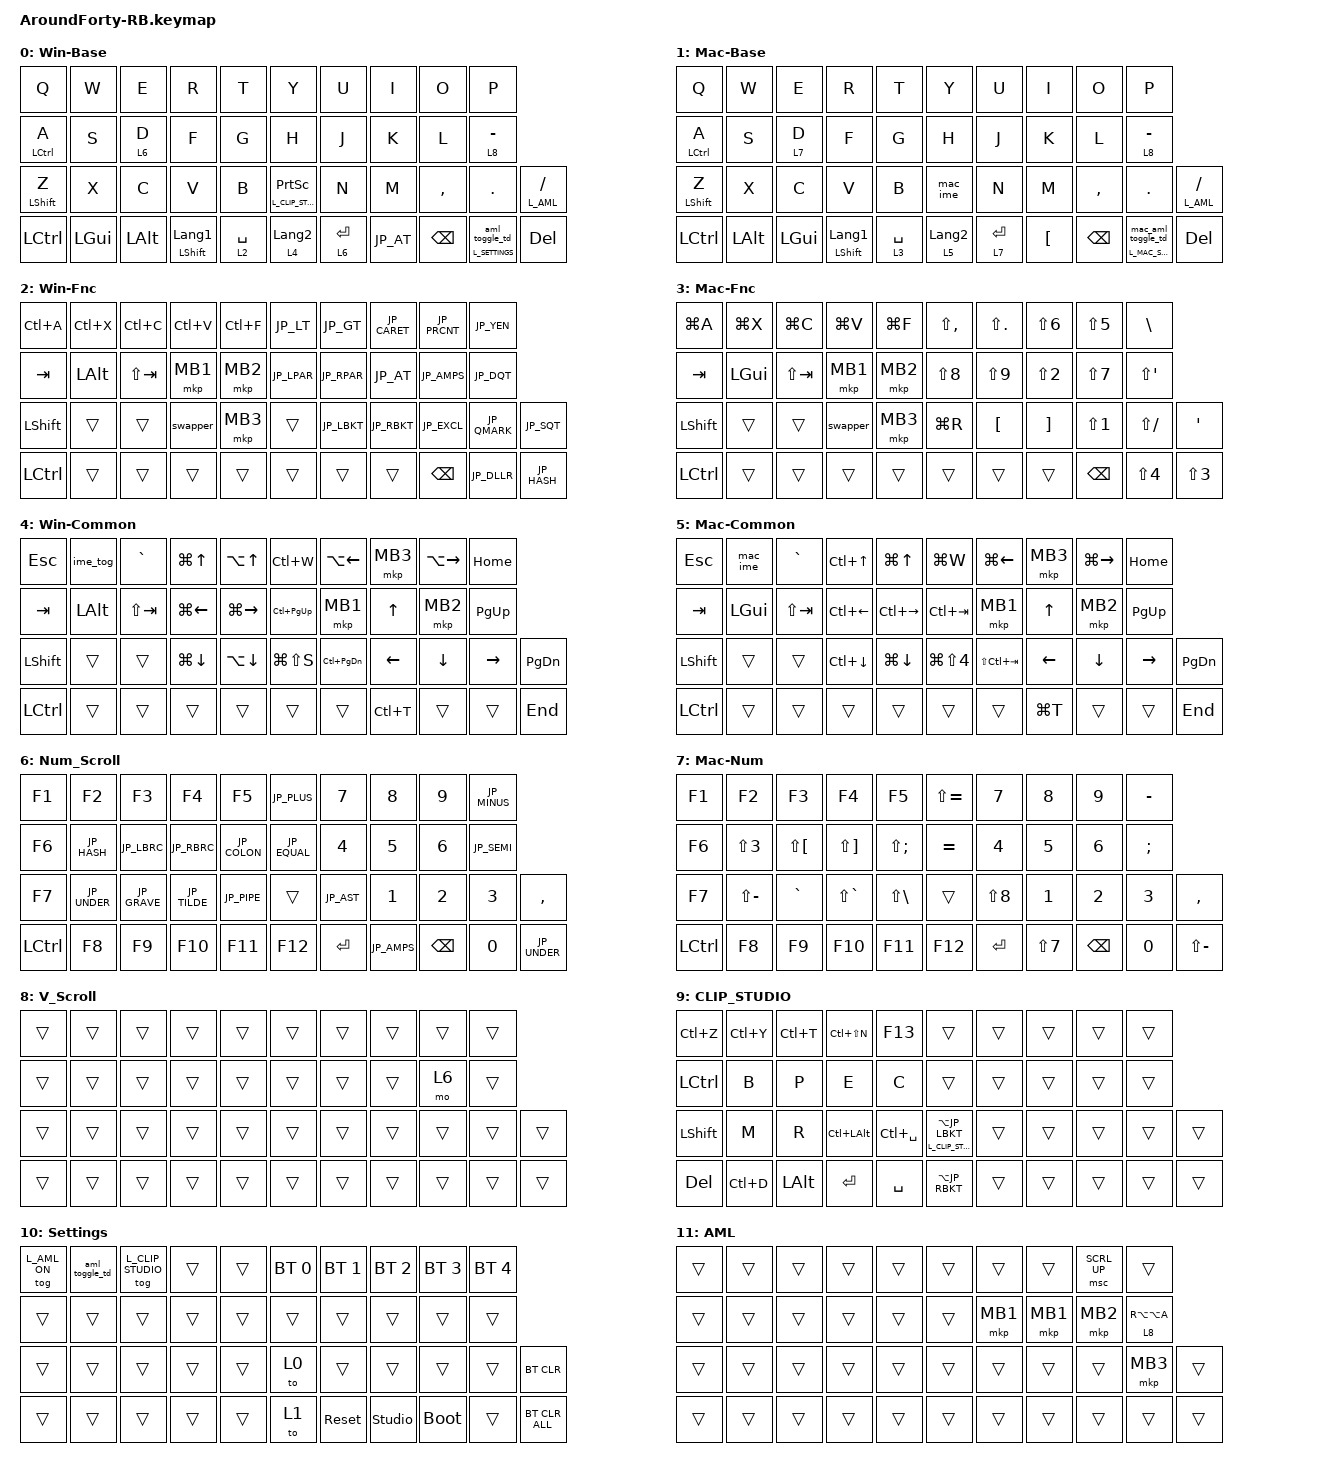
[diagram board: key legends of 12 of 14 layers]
#include<behaviors/rgbled_widget.dtsi>
#include <behaviors.dtsi>
#include <dt-bindings/zmk/bt.h>
#include <dt-bindings/zmk/keys.h>
#include <dt-bindings/zmk/pointing.h>

// JIS配列用の記号変換マクロ
#define JP_LT LS(COMMA)           // <
#define JP_GT LS(DOT)             // >
#define JP_CARET EQUAL            // ^
#define JP_PRCNT LS(N5)           // %
#define JP_DLLR LS(N4)            // $
#define JP_LPAR LS(N8)            // (
#define JP_RPAR LS(N9)            // )
#define JP_AT LEFT_BRACKET        // @
#define JP_AMPS LS(N6)            // &
#define JP_DQT LS(N2)             // "
#define JP_COLON SINGLE_QUOTE     // :
#define JP_LBKT RIGHT_BRACKET     // [
#define JP_RBKT NON_US_HASH       // ]
#define JP_EXCL LS(N1)            // !
#define JP_QMARK LS(SLASH)        // ?
#define JP_SQT LS(N7)             // '
#define JP_YEN INTERNATIONAL_3    // Yen (Backslash)
#define JP_HASH LS(N3)            // #
#define JP_MINUS MINUS            // -
#define JP_PLUS LS(SEMICOLON)     // +
#define JP_AST LS(SINGLE_QUOTE)   // *
#define JP_EQUAL LS(MINUS)        // =
#define JP_SEMI SEMICOLON            // ;
#define JP_UNDER LS(INTERNATIONAL_1) // _
#define JP_TILDE LS(EQUAL)           // ~
#define JP_PIPE LS(INTERNATIONAL_3)  // |
#define JP_GRAVE LS(LEFT_BRACKET)    // `
#define JP_LBRC LS(RIGHT_BRACKET)    // {
#define JP_RBRC LS(NON_US_HASH)      // }

// Higher layer numbers take precedence. CLIP_STUDIO stays below both Settings layers.
#define L_CLIP_STUDIO 9
#define L_SETTINGS 10
#define L_AML 11
#define L_AML_ON 12
#define L_MAC_SETTINGS 13

&mt {
    flavor = "balanced";
    quick-tap-ms = <0>;
};

/ {
    behaviors {
        // Internal split command; the central sends the actual layer state.
        af_led: af_led {
            compatible = "zmk,behavior-aroundforty-status-led";
            #binding-cells = <1>;
            clip-layer = <L_CLIP_STUDIO>;
            aml-layer = <L_AML>;
            aml-on-layer = <L_AML_ON>;
        };
    };

    combos {
        compatible = "zmk,combos";

        Escape {
            bindings = <&kp ESCAPE>;
            key-positions = <0 1>;
        };
    };

    macros {
        to_layer_0: to_layer_0 {
            compatible = "zmk,behavior-macro-one-param";
            #binding-cells = <1>;
            bindings = <&to 0 &macro_param_1to1 &kp MACRO_PLACEHOLDER>;
            label = "TO_LAYER_0";
        };

        // Windows用入力切り替え：Win + Space
        ime_tog: ime_toggle {
            compatible = "zmk,behavior-macro";
            #binding-cells = <0>;
            bindings =
                <&macro_press>,
                <&kp LGUI>,
                <&macro_tap>,
                <&kp SPACE>,
                <&macro_release>,
                <&kp LGUI>;
        };

        // macOS用入力切り替え：Ctrl + Space
        mac_ime: mac_ime_toggle {
            compatible = "zmk,behavior-macro";
            #binding-cells = <0>;
            bindings =
                <&macro_press>,
                <&kp LCTRL>,
                <&macro_tap>,
                <&kp SPACE>,
                <&macro_release>,
                <&kp LCTRL>;
        };

        // AMLだけ確定OFFにする。クリスタとOSベースは維持する。
        aml_off: aml_off {
            compatible = "zmk,behavior-macro";
            #binding-cells = <0>;
            label = "AML_OFF";
            wait-ms = <0>;
            bindings
                = <&macro_release>, <&mo L_AML_ON>, <&mo L_AML>;
        };

        aml_toggle_td: aml_toggle_td {
            compatible = "zmk,behavior-tap-dance";
            #binding-cells = <0>;
            label = "AML_TOGGLE_TD";
            tapping-term-ms = <300>;
            bindings = <&aml_off>, <&tog L_AML_ON>;
        };

        // Mac側もAMLだけ解除し、クリスタとUS配列を維持する。
        mac_aml_off: mac_aml_off {
            compatible = "zmk,behavior-macro";
            #binding-cells = <0>;
            label = "MAC_AML_OFF";
            wait-ms = <0>;
            bindings
                = <&macro_release>, <&mo L_AML_ON>, <&mo L_AML>;
        };

        mac_aml_toggle_td: mac_aml_toggle_td {
            compatible = "zmk,behavior-tap-dance";
            #binding-cells = <0>;
            label = "MAC_AML_TOGGLE_TD";
            tapping-term-ms = <300>;
            bindings = <&mac_aml_off>, <&tog L_AML_ON>;
        };
    };

    behaviors {
        lt_to_layer_0: lt_to_layer_0 {
            compatible = "zmk,behavior-hold-tap";
            label = "LAYER_TAP_TO_0";
            bindings = <&mo>, <&to_layer_0>;
            #binding-cells = <2>;
            tapping-term-ms = <200>;
        };

        lt_num: lt_num {
            compatible = "zmk,behavior-hold-tap";
            label = "LT_NUM";
            bindings = <&mo>, <&kp>;
            #binding-cells = <2>;
            tapping-term-ms = <150>;
            quick-tap-ms = <150>;        // これを入れると Enter の連打が可能になります
        };

        mt_z_shift: mt_z_shift {
            compatible = "zmk,behavior-hold-tap";
            label = "MT_Z_SHIFT";
            bindings = <&kp>, <&kp>;
            #binding-cells = <2>;
            flavor = "balanced";
            quick-tap-ms = <0>;
            tapping-term-ms = <250>;
        };

        mt_a_ctrl: mt_a_ctrl {
            compatible = "zmk,behavior-hold-tap";
            label = "MT_A_CTRL";
            bindings = <&kp>, <&kp>;
            #binding-cells = <2>;
            flavor = "balanced";
            quick-tap-ms = <0>;
            tapping-term-ms = <250>;
        };

        lt_typ: layer_tap_typing {
            compatible = "zmk,behavior-hold-tap";
            label = "LAYER_TAP_TYPING";
            #binding-cells = <2>;
            tapping-term-ms = <200>;
            flavor = "tap-preferred";
            require-prior-idle-ms = <150>;
            bindings = <&mo>, <&kp>;
        };

        lt_clip_toggle: clip_toggle_hold_tap {
            compatible = "zmk,behavior-hold-tap";
            label = "CLIP_TOGGLE_HOLD_TAP";
            #binding-cells = <2>;
            tapping-term-ms = <200>;
            flavor = "tap-preferred";
            quick-tap-ms = <0>;
            bindings = <&tog>, <&kp>;
        };

        settings_hold_tap: settings_hold_tap {
            compatible = "zmk,behavior-hold-tap";
            label = "SETTINGS_HOLD_TAP";
            #binding-cells = <2>;
            tapping-term-ms = <200>;
            flavor = "balanced";
            quick-tap-ms = <0>;
            bindings = <&mo>, <&aml_toggle_td>;
        };

        mac_settings_hold_tap: mac_settings_hold_tap {
            compatible = "zmk,behavior-hold-tap";
            label = "MAC_SETTINGS_HOLD_TAP";
            #binding-cells = <2>;
            tapping-term-ms = <200>;
            flavor = "balanced";
            quick-tap-ms = <0>;
            bindings = <&mo>, <&mac_aml_toggle_td>;
        };

        scroll_up_down: behavior_sensor_rotate_mouse_wheel_up_down {
            compatible = "zmk,behavior-sensor-rotate";
            #sensor-binding-cells = <0>;
            bindings = <&msc SCRL_UP>, <&msc SCRL_DOWN>;
            tap-ms = <20>;
        };

        swapper: swapper {
            compatible = "zmk,behavior-tri-state";
            #binding-cells = <0>;
            bindings = <&kt LALT>, <&kp TAB>, <&kt LALT>;
        };
    };

    keymap {
        compatible = "zmk,keymap";

        Win-Base { // layer 0
            display-name = "Win-Base";
            bindings = <
                &kp Q                    &kp W          &kp E          &kp R                  &kp T                  &kp Y                   &kp U            &kp I             &kp O             &kp P
                &mt_a_ctrl LCTRL A       &kp S          &lt_typ 6 D      &kp F                  &kp G                  &kp H                   &kp J            &kp K             &kp L             &lt 8 MINUS
                &mt_z_shift LEFT_SHIFT Z &kp X          &kp C          &kp V                  &kp B                  &lt_clip_toggle L_CLIP_STUDIO PRINTSCREEN &kp N            &kp M             &kp COMMA         &kp DOT   &lt L_AML SLASH
                &kp LCTRL                &kp LGUI       &kp LALT       &mt LSHFT LANGUAGE_1   &lt 2 SPACE            &lt 4 LANGUAGE_2        &lt_num 6 ENTER  &kp JP_AT         &kp BSPC          &settings_hold_tap L_SETTINGS 0 &kp DEL
            >;
        };

        Mac-Base { // layer 1
            display-name = "Mac-Base";
            bindings = <
                &kp Q                    &kp W          &kp E          &kp R                  &kp T                  &kp Y                   &kp U            &kp I             &kp O             &kp P
                &mt_a_ctrl LCTRL A       &kp S          &lt_typ 7 D      &kp F                  &kp G                  &kp H                   &kp J            &kp K             &kp L             &lt 8 MINUS
                &mt_z_shift LEFT_SHIFT Z &kp X          &kp C          &kp V                  &kp B                  &mac_ime                &kp N            &kp M             &kp COMMA         &kp DOT   &lt L_AML SLASH
                &kp LCTRL                &kp LEFT_ALT   &kp LEFT_GUI   &mt LSHFT LANGUAGE_1   &lt 3 SPACE            &lt 5 LANGUAGE_2        &lt_num 7 ENTER  &kp LEFT_BRACKET  &kp BSPC          &mac_settings_hold_tap L_MAC_SETTINGS 0 &kp DEL
            >;
        };

        Win-Fnc { // layer 2
            display-name = "Win-Fnc";
            bindings = <
                &kp LC(A)                &kp LC(X)      &kp LC(C)      &kp LC(V)              &kp LC(F)              &kp JP_LT               &kp JP_GT        &kp JP_CARET      &kp JP_PRCNT      &kp JP_YEN
                &kp TAB                  &kp LEFT_ALT   &kp LS(TAB)    &mkp MB1               &mkp MB2               &kp JP_LPAR             &kp JP_RPAR      &kp JP_AT         &kp JP_AMPS       &kp JP_DQT
                &kp LEFT_SHIFT           &trans         &trans         &swapper               &mkp MB3               &trans                  &kp JP_LBKT      &kp JP_RBKT       &kp JP_EXCL       &kp JP_QMARK &kp JP_SQT
                &kp LCTRL                &trans         &trans         &trans                 &trans                 &trans                  &trans           &trans            &kp BACKSPACE     &kp JP_DLLR &kp JP_HASH
            >;
        };

        Mac-Fnc { // layer 3
            display-name = "Mac-Fnc";
            bindings = <
                &kp LG(A)                &kp LG(X)      &kp LG(C)      &kp LG(V)              &kp LG(F)              &kp LS(COMMA)           &kp LS(DOT)      &kp LS(N6)        &kp LS(N5)        &kp BACKSLASH
                &kp TAB                  &kp LEFT_GUI   &kp LS(TAB)    &mkp MB1               &mkp MB2               &kp LS(N8)              &kp LS(N9)       &kp LS(N2)        &kp LS(N7)        &kp LS(SINGLE_QUOTE)
                &kp LEFT_SHIFT           &trans         &trans         &swapper               &mkp MB3               &kp LG(R)               &kp LEFT_BRACKET &kp RIGHT_BRACKET &kp LS(N1)        &kp LS(SLASH) &kp SINGLE_QUOTE
                &kp LCTRL                &trans         &trans         &trans                 &trans                 &trans                  &trans           &trans            &kp BACKSPACE     &kp LS(N4)   &kp LS(N3)
            >;
        };

        Win-Common { // layer 4
            display-name = "Win-Common";
            bindings = <
                &kp ESC                  &ime_tog       &kp GRAVE      &kp LG(UP_ARROW)       &kp LA(UP_ARROW)       &kp LC(W)               &kp LA(LEFT_ARROW) &mkp MB3         &kp LA(RIGHT_ARROW) &kp HOME
                &kp TAB                  &kp LEFT_ALT   &kp LS(TAB)    &kp LG(LEFT_ARROW)     &kp LG(RIGHT_ARROW)    &kp LC(PAGE_UP)         &mkp MB1           &kp UP_ARROW     &mkp MB2            &kp PAGE_UP
                &kp LSHFT                &trans         &trans         &kp LG(DOWN_ARROW)     &kp LA(DOWN_ARROW)     &kp LG(LS(S))           &kp LC(PAGE_DOWN)  &kp LEFT_ARROW   &kp DOWN_ARROW      &kp RIGHT_ARROW &kp PAGE_DOWN
                &kp LCTRL                &trans         &trans         &trans                 &trans                 &trans                  &trans             &kp LC(T)        &trans              &trans        &kp END
            >;
        };

        Mac-Common { // layer 5
            display-name = "Mac-Common";
            bindings = <
                &kp ESC                  &mac_ime       &kp GRAVE      &kp LC(UP_ARROW)       &kp LG(UP_ARROW)       &kp LG(W)               &kp LG(LEFT_ARROW) &mkp MB3         &kp LG(RIGHT_ARROW) &kp HOME
                &kp TAB                  &kp LEFT_GUI   &kp LS(TAB)    &kp LC(LEFT_ARROW)     &kp LC(RIGHT_ARROW)    &kp LC(TAB)             &mkp MB1           &kp UP_ARROW     &mkp MB2            &kp PAGE_UP
                &kp LSHFT                &trans         &trans         &kp LC(DOWN_ARROW)     &kp LG(DOWN_ARROW)     &kp LG(LS(N4))          &kp LS(LC(TAB))    &kp LEFT_ARROW   &kp DOWN_ARROW      &kp RIGHT_ARROW &kp PAGE_DOWN
                &kp LCTRL                &trans         &trans         &trans                 &trans                 &trans                  &trans             &kp LG(T)        &trans              &trans        &kp END
            >;
        };

        Num_Scroll { // layer 6
            bindings = <
                    &kp F1                   &kp F2         &kp F3         &kp F4                 &kp F5                 &kp JP_PLUS             &kp N7            &kp N8            &kp N9            &kp JP_MINUS
                    &kp F6                   &kp JP_HASH         &kp JP_LBRC    &kp JP_RBRC            &kp JP_COLON           &kp JP_EQUAL            &kp N4            &kp N5            &kp N6            &kp JP_SEMI
                    &kp F7                   &kp JP_UNDER         &kp JP_GRAVE   &kp JP_TILDE           &kp JP_PIPE            &trans                  &kp JP_AST        &kp N1            &kp N2            &kp N3          &kp COMMA
                    &kp LCTRL                &kp F8         &kp F9         &kp F10                &kp F11                &kp F12                 &kp ENTER         &kp JP_AMPS       &kp BSPC          &kp N0        &kp JP_UNDER
            >;
        };

        Mac_Num_Scroll { // layer 7
            display-name = "Mac-Num";
            bindings = <
                    &kp F1                   &kp F2         &kp F3         &kp F4                 &kp F5                 &kp LS(EQUAL)           &kp N7            &kp N8            &kp N9            &kp MINUS
                    &kp F6                   &kp LS(N3)     &kp LS(LEFT_BRACKET) &kp LS(RIGHT_BRACKET) &kp LS(SEMICOLON)  &kp EQUAL               &kp N4            &kp N5            &kp N6            &kp SEMICOLON
                    &kp F7                   &kp LS(MINUS)  &kp GRAVE      &kp LS(GRAVE)          &kp LS(BACKSLASH)      &trans                  &kp LS(N8)            &kp N1         &kp N2            &kp N3          &kp COMMA
                    &kp LCTRL                &kp F8         &kp F9         &kp F10                &kp F11                &kp F12             &kp ENTER         &kp LS(N7)        &kp BSPC          &kp N0          &kp LS(MINUS)
            >;
        };

        V_Scroll { // layer 8
            bindings = <
                &trans                   &trans         &trans         &trans                 &trans                 &trans                  &trans            &trans            &trans            &trans
                &trans                   &trans         &trans         &trans                 &trans                 &trans                  &trans            &trans            &mo 6             &trans
                &trans                   &trans         &trans         &trans                 &trans                 &trans                  &trans            &trans            &trans            &trans        &trans
                &trans                   &trans         &trans         &trans                 &trans                 &trans                  &trans            &trans            &trans            &trans        &trans
            >;
        };

        CLIP_STUDIO { // layer 9: Windows/JIS CLIP STUDIO PAINT shortcuts
            display-name = "CLIP_STUDIO";
            bindings = <
                &kp LC(Z)         &kp LC(Y)         &kp LC(T)         &kp LC(LS(N))     &kp F13           &trans             &trans       &trans       &trans       &trans
                &kp LCTRL         &kp B             &kp P             &kp E             &kp C             &trans             &trans       &trans       &trans       &trans
                &kp LSHFT         &kp M             &kp R             &kp LC(LALT)      &kp LC(SPACE)     &lt_clip_toggle L_CLIP_STUDIO LA(JP_LBKT) &trans &trans &trans &trans &trans
                &kp DELETE        &kp LC(D)         &kp LALT          &kp ENTER         &kp SPACE         &kp LA(JP_RBKT)   &trans       &trans       &trans       &trans       &trans
            >;
        };

        Settings { // layer 10
            display-name = "Settings";
            bindings = <
                &tog L_AML_ON /* AML ON */ &aml_toggle_td &tog L_CLIP_STUDIO &trans              &trans                 &bt BT_SEL 0            &bt BT_SEL 1      &bt BT_SEL 2      &bt BT_SEL 3      &bt BT_SEL 4
                &trans                   &trans         &trans         &trans                 &trans                 &trans                  &trans            &trans            &trans            &trans
                &trans                   &trans         &trans         &trans                 &trans                 &to 0 /* win JIS*/      &trans            &trans            &trans            &trans        &bt BT_CLR
                &trans                   &trans         &trans         &trans                 &trans                 &to 1 /* mac US*/       &sys_reset        &studio_unlock    &bootloader       &trans        &bt BT_CLR_ALL
            >;
        };

        AML { // layer 11
            display-name = "AML";
            bindings = <
                &trans                   &trans         &trans         &trans                 &trans                 &trans                  &trans            &trans            &msc SCRL_UP      &trans
                &trans                   &trans         &trans         &trans                 &trans                 &trans                  &mkp MB1          &mkp MB1          &mkp MB2          &lt 8 RA(LA(A))
                &trans                   &trans         &trans         &trans                 &trans                 &trans                  &trans            &trans            &trans            &mkp MB3      &trans
                &trans                   &trans         &trans         &trans                 &trans                 &trans                  &trans            &trans            &trans            &trans        &trans
            >;
        };

        AML-On { // layer 12 — AML自動発動を有効にするフラグレイヤー（キーはすべてtrans）
            display-name = "AML-On";
            bindings = <
                &trans &trans &trans &trans &trans &trans &trans &trans &trans &trans
                &trans &trans &trans &trans &trans &trans &trans &trans &trans &trans
                &trans &trans &trans &trans &trans &trans &trans &trans &trans &trans &trans
                &trans &trans &trans &trans &trans &trans &trans &trans &trans &trans &trans
            >;
        };

        Mac-Settings { // layer 13
            display-name = "Mac-Settings";
            bindings = <
                &tog L_AML_ON /* AML ON */ &mac_aml_toggle_td &tog L_CLIP_STUDIO &trans           &trans                 &bt BT_SEL 0            &bt BT_SEL 1      &bt BT_SEL 2      &bt BT_SEL 3      &bt BT_SEL 4
                &trans                   &trans         &trans         &trans                 &trans                 &trans                  &trans            &trans            &trans            &trans
                &trans                   &trans         &trans         &trans                 &trans                 &to 0 /* win JIS */     &trans            &trans            &trans            &trans        &bt BT_CLR
                &trans                   &trans         &trans         &trans                 &trans                 &to 1 /* mac US */      &sys_reset        &studio_unlock    &bootloader       &trans        &bt BT_CLR_ALL
            >;
        };
    };
};
